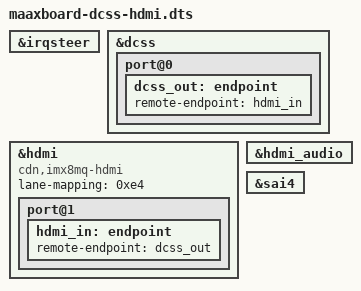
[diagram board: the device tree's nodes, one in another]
/*
 * Copyright 2019 EMBEST
 *
 * This program is free software; you can redistribute it and/or
 * modify it under the terms of the GNU General Public License
 * as published by the Free Software Foundation; either version 2
 * of the License, or (at your option) any later version.
 *
 * This program is distributed in the hope that it will be useful,
 * but WITHOUT ANY WARRANTY; without even the implied warranty of
 * MERCHANTABILITY or FITNESS FOR A PARTICULAR PURPOSE.  See the
 * GNU General Public License for more details.
 */

#include "maaxboard.dtsi"
#include "maaxboard-extended-gpio.dtsi"

&irqsteer {
	status = "okay";
};

&dcss {
	status = "okay";

	port@0 {
		dcss_out: endpoint {
			  remote-endpoint = <&hdmi_in>;
		};
	};
};

&hdmi {
	compatible = "cdn,imx8mq-hdmi";
	lane-mapping = <0xe4>;
	status = "okay";

	port@1 {
		hdmi_in: endpoint {
			remote-endpoint = <&dcss_out>;
		};
	};
};

&hdmi_audio {
	status = "okay";
};

&sai4 {
	status = "okay";
};
